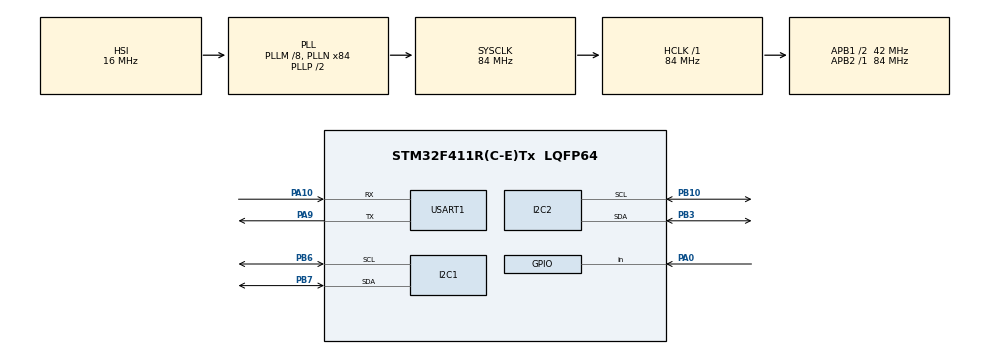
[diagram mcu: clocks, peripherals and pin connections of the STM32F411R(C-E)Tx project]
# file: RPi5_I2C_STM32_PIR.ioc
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Mcu.Family=STM32F4
Mcu.Name=STM32F411R(C-E)Tx
Mcu.Package=LQFP64
NVIC.I2C1_ER_IRQn=true\:0\:0\:false\:false\:true\:true\:true\:true
NVIC.I2C1_EV_IRQn=true\:0\:0\:false\:false\:true\:true\:true\:true
NVIC.PriorityGroup=NVIC_PRIORITYGROUP_0
PA0-WKUP.Signal=GPIO_Input
PA10.Mode=Asynchronous
PA10.Signal=USART1_RX
PA9.Mode=Asynchronous
PA9.Signal=USART1_TX
PB10.Mode=I2C
PB10.Signal=I2C2_SCL
PB3.Mode=I2C
PB3.Signal=I2C2_SDA
PB6.Mode=I2C
PB6.Signal=I2C1_SCL
PB7.Mode=I2C
PB7.Signal=I2C1_SDA
ProjectManager.HeapSize=0x200
ProjectManager.StackSize=0x400
ProjectManager.TargetToolchain=STM32CubeIDE
RCC.48MHZClocksFreq_Value=84000000
RCC.AHBFreq_Value=84000000
RCC.APB1CLKDivider=RCC_HCLK_DIV2
RCC.APB1Freq_Value=42000000
RCC.APB1TimFreq_Value=84000000
RCC.APB2Freq_Value=84000000
RCC.APB2TimFreq_Value=84000000
RCC.CortexFreq_Value=84000000
RCC.FLatency-AdvancedSettings=FLASH_LATENCY_2
RCC.HCLKFreq_Value=84000000
RCC.HSE_VALUE=8000000
RCC.HSI_VALUE=16000000
RCC.PLLN=336
RCC.PLLP=RCC_PLLP_DIV4
RCC.SYSCLKFreq_VALUE=84000000
RCC.SYSCLKSource=RCC_SYSCLKSOURCE_PLLCLK
RCC.VCOOutputFreq_Value=336000000
USART1.VirtualMode=VM_ASYNC
board=NUCLEO-F411RE

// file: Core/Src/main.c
/* USER CODE BEGIN Header */
/**
  ******************************************************************************
  * @file           : main.c
  * @brief          : Main program body
  ******************************************************************************
  * @attention
  *
  * Copyright (c) 2025 STMicroelectronics.
  * All rights reserved.
  *
  * This software is licensed under terms that can be found in the LICENSE file
  * in the root directory of this software component.
  * If no LICENSE file comes with this software, it is provided AS-IS.
  *
  ******************************************************************************
  */
/* USER CODE END Header */
#include "main.h"
#include<stdio.h>

I2C_HandleTypeDef hi2c1;
I2C_HandleTypeDef hi2c2;

UART_HandleTypeDef huart1;

/* USER CODE BEGIN PV */
uint8_t tx_buffer[3];      // [motion(0/1), lux_hi, lux_lo]
uint8_t bh1750_raw[2];     // raw two bytes from BH1750

/* USER CODE END PV */

void SystemClock_Config(void);
static void MX_GPIO_Init(void);
static void MX_I2C1_Init(void);
static void MX_I2C2_Init(void);
static void MX_USART1_UART_Init(void);
/* USER CODE BEGIN PFP */
/* simple printf retarget to USART2 */
int __io_putchar(int ch) { HAL_UART_Transmit(&huart1, (uint8_t *)&ch, 1, HAL_MAX_DELAY); return ch; }

/* USER CODE END PFP */

/* USER CODE BEGIN 0 */
/* Optional: BH1750 address (7-bit) */
#define BH1750_ADDR (0x23 << 1) // left-shifted for HAL functions (address in HAL functions is 8-bit)
#define STM32_SLAVE_ADDR (0x27 << 1) // cubeMX often stores shifted; ensure consistency

/* USER CODE END 0 */

int main(void)
{

  /* MCU Configuration--------------------------------------------------------*/

  /* Reset of all peripherals, Initializes the Flash interface and the Systick. */
  HAL_Init();

  /* Configure the system clock */
  SystemClock_Config();

  /* Initialize all configured peripherals */
  MX_GPIO_Init();
  MX_I2C1_Init();
  MX_I2C2_Init();
  MX_USART1_UART_Init();
  /* USER CODE BEGIN 2 */
  printf("Focus Monitor: started\r\n");

    /* Prepare initial tx buffer */
    tx_buffer[0] = 0;
    tx_buffer[1] = 0;
    tx_buffer[2] = 0;

    /* Ensure slave transmit IT is primed (non-blocking). We'll re-arm when data updates. */
    HAL_I2C_Slave_Transmit_IT(&hi2c1, tx_buffer, 3);

  /* USER CODE END 2 */

  /* Infinite loop */
  while (1)
  {
	  /* ---------- 1) Read PIR (PA0) ---------- */
	      uint8_t motion = (uint8_t)HAL_GPIO_ReadPin(GPIOA, GPIO_PIN_0); // 0 or 1
	      tx_buffer[0] = motion;

	      /* ---------- 2) Read BH1750 ---------- */
	      // Command: 0x10 = Continuously H-Resolution Mode (or use one-time 0x20)
	      uint8_t cmd = 0x10;
	      if (HAL_I2C_Master_Transmit(&hi2c2, BH1750_ADDR, &cmd, 1, 100) == HAL_OK)
	      {
	        HAL_Delay(180); // measurement time for high res
	        if (HAL_I2C_Master_Receive(&hi2c2, BH1750_ADDR, bh1750_raw, 2, 100) == HAL_OK)
	        {
	          tx_buffer[1] = bh1750_raw[0];
	          tx_buffer[2] = bh1750_raw[1];
	        }
	        else
	        {
	          // read failed
	          tx_buffer[1] = 0;
	          tx_buffer[2] = 0;
	        }
	      }
	      else
	      {
	        // write cmd failed
	        tx_buffer[1] = 0;
	        tx_buffer[2] = 0;
	      }

	      /* Debug print */
	      uint16_t lux = ((uint16_t)tx_buffer[1] << 8) | tx_buffer[2];
	      // BH1750 raw -> lux conversion: value/1.2 (use float if needed). For console, show raw.
	      printf("Motion=%d, BH1750_raw=%u\r\n", motion, lux);

	      /* (Re)arm slave transmit with updated buffer */
	          // Only arm transmit if I2C is ready; otherwise skip and try next loop
	          if (HAL_I2C_GetState(&hi2c1) == HAL_I2C_STATE_READY)
	          {
	              // Non-blocking transmit — STM32 will send buffer when Pi reads
	              if (HAL_I2C_Slave_Transmit_IT(&hi2c1, tx_buffer, 3) != HAL_OK)
	              {
	                  // optionally log error via UART
	                  printf("I2C Slave Transmit_IT error\r\n");
	              }
	          }
	          else
	          {
	              // Optional: print state for debugging (comment out if noisy)
	              // printf("I2C busy: state=%lu\r\n", HAL_I2C_GetState(&hi2c1));
	          }
	      HAL_Delay(800); // sampling interval ~ 1s

  }
}

void SystemClock_Config(void)
{
  RCC_OscInitTypeDef RCC_OscInitStruct = {0};
  RCC_ClkInitTypeDef RCC_ClkInitStruct = {0};

  /** Configure the main internal regulator output voltage
  */
  __HAL_RCC_PWR_CLK_ENABLE();
  __HAL_PWR_VOLTAGESCALING_CONFIG(PWR_REGULATOR_VOLTAGE_SCALE1);

  /** Initializes the RCC Oscillators according to the specified parameters
  * in the RCC_OscInitTypeDef structure.
  */
  RCC_OscInitStruct.OscillatorType = RCC_OSCILLATORTYPE_HSI;
  RCC_OscInitStruct.HSIState = RCC_HSI_ON;
  RCC_OscInitStruct.HSICalibrationValue = RCC_HSICALIBRATION_DEFAULT;
  RCC_OscInitStruct.PLL.PLLState = RCC_PLL_ON;
  RCC_OscInitStruct.PLL.PLLSource = RCC_PLLSOURCE_HSI;
  RCC_OscInitStruct.PLL.PLLM = 8;
  RCC_OscInitStruct.PLL.PLLN = 84;
  RCC_OscInitStruct.PLL.PLLP = RCC_PLLP_DIV2;
  RCC_OscInitStruct.PLL.PLLQ = 4;
  if (HAL_RCC_OscConfig(&RCC_OscInitStruct) != HAL_OK)
  {
    Error_Handler();
  }

  /** Initializes the CPU, AHB and APB buses clocks
  */
  RCC_ClkInitStruct.ClockType = RCC_CLOCKTYPE_HCLK|RCC_CLOCKTYPE_SYSCLK
                              |RCC_CLOCKTYPE_PCLK1|RCC_CLOCKTYPE_PCLK2;
  RCC_ClkInitStruct.SYSCLKSource = RCC_SYSCLKSOURCE_PLLCLK;
  RCC_ClkInitStruct.AHBCLKDivider = RCC_SYSCLK_DIV1;
  RCC_ClkInitStruct.APB1CLKDivider = RCC_HCLK_DIV2;
  RCC_ClkInitStruct.APB2CLKDivider = RCC_HCLK_DIV1;

  if (HAL_RCC_ClockConfig(&RCC_ClkInitStruct, FLASH_LATENCY_2) != HAL_OK)
  {
    Error_Handler();
  }
}

static void MX_I2C1_Init(void)
{

  hi2c1.Instance = I2C1;
  hi2c1.Init.ClockSpeed = 100000;
  hi2c1.Init.DutyCycle = I2C_DUTYCYCLE_2;
  hi2c1.Init.OwnAddress1 = STM32_SLAVE_ADDR;;
  hi2c1.Init.AddressingMode = I2C_ADDRESSINGMODE_7BIT;
  hi2c1.Init.DualAddressMode = I2C_DUALADDRESS_DISABLE;
  hi2c1.Init.OwnAddress2 = 0;
  hi2c1.Init.GeneralCallMode = I2C_GENERALCALL_DISABLE;
  hi2c1.Init.NoStretchMode = I2C_NOSTRETCH_DISABLE;
  if (HAL_I2C_Init(&hi2c1) != HAL_OK)
  {
    Error_Handler();
  }

}

static void MX_I2C2_Init(void)
{

  hi2c2.Instance = I2C2;
  hi2c2.Init.ClockSpeed = 100000;
  hi2c2.Init.DutyCycle = I2C_DUTYCYCLE_2;
  hi2c2.Init.OwnAddress1 = 0;
  hi2c2.Init.AddressingMode = I2C_ADDRESSINGMODE_7BIT;
  hi2c2.Init.DualAddressMode = I2C_DUALADDRESS_DISABLE;
  hi2c2.Init.OwnAddress2 = 0;
  hi2c2.Init.GeneralCallMode = I2C_GENERALCALL_DISABLE;
  hi2c2.Init.NoStretchMode = I2C_NOSTRETCH_DISABLE;
  if (HAL_I2C_Init(&hi2c2) != HAL_OK)
  {
    Error_Handler();
  }

}

static void MX_USART1_UART_Init(void)
{

  huart1.Instance = USART1;
  huart1.Init.BaudRate = 115200;
  huart1.Init.WordLength = UART_WORDLENGTH_8B;
  huart1.Init.StopBits = UART_STOPBITS_1;
  huart1.Init.Parity = UART_PARITY_NONE;
  huart1.Init.Mode = UART_MODE_TX_RX;
  huart1.Init.HwFlowCtl = UART_HWCONTROL_NONE;
  huart1.Init.OverSampling = UART_OVERSAMPLING_16;
  if (HAL_UART_Init(&huart1) != HAL_OK)
  {
    Error_Handler();
  }

}

static void MX_GPIO_Init(void)
{
  GPIO_InitTypeDef GPIO_InitStruct = {0};

  /* GPIO Ports Clock Enable */
  __HAL_RCC_GPIOA_CLK_ENABLE();
  __HAL_RCC_GPIOB_CLK_ENABLE();

  /*Configure GPIO pin : PA0 */
  GPIO_InitStruct.Pin = GPIO_PIN_0;
  GPIO_InitStruct.Mode = GPIO_MODE_INPUT;
  GPIO_InitStruct.Pull = GPIO_NOPULL;
  HAL_GPIO_Init(GPIOA, &GPIO_InitStruct);

}

void Error_Handler(void)
{
  __disable_irq();
  while (1)
  {
  }
}
